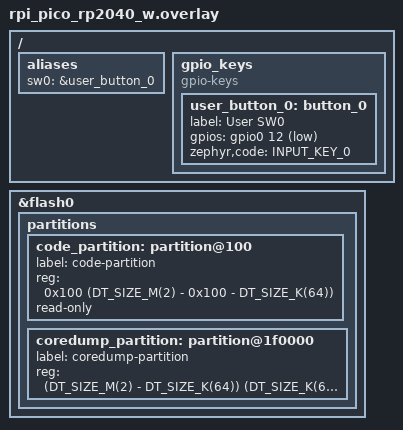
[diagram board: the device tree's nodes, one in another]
/* Enable user to attach a button that will trigger a core dump (button A on Pico Explorer) */
#include <zephyr/dt-bindings/input/input-event-codes.h>
/ {
	aliases {
		/* make an alias so we can refer to “sw0” in code */
		sw0 = &user_button_0;
	};

	gpio_keys {
		compatible = "gpio-keys";
		user_button_0: button_0 {
			label = "User SW0";
			gpios = <&gpio0 12 (GPIO_ACTIVE_LOW | GPIO_PULL_UP)>;
			zephyr,code = <INPUT_KEY_0>;
			status = "okay";
		};
	};
};

/delete-node/ &code_partition;

&flash0 {
	/* Reserve last 64 KiB for core dumps */
	partitions {
		code_partition: partition@100 {
			label = "code-partition";
			reg = <0x100 (DT_SIZE_M(2) - 0x100 - DT_SIZE_K(64))>;
			read-only;
		};
		coredump_partition: partition@1f0000 {
			label = "coredump-partition";
			reg = <(DT_SIZE_M(2) - DT_SIZE_K(64)) (DT_SIZE_K(64))>;
		};
	};
};
